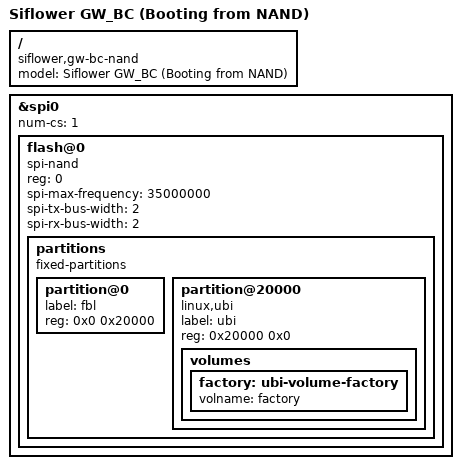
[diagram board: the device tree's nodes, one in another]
/dts-v1/;
#include "sf21h8898-gw-bc.dtsi"


/ {
	model = "Siflower GW_BC (Booting from NAND)";
	compatible = "siflower,gw-bc-nand", "siflower,sf21h8898";
};

&spi0 {
	status = "okay";
	num-cs = <1>;

	flash@0 {
		compatible = "spi-nand";
		reg = <0>;
		spi-max-frequency = <35000000>;
		spi-tx-bus-width = <2>;
		spi-rx-bus-width = <2>;
		#address-cells = <1>;
		#size-cells = <1>;

	        partitions {
			compatible = "fixed-partitions";
			#address-cells = <1>;
			#size-cells = <1>;

			partition@0 {
				label = "fbl";
				reg = <0x0 0x20000>;
			};

			partition@20000 {
				label = "ubi";
				reg = <0x20000 0x0>;
				compatible = "linux,ubi";

				volumes {
					factory: ubi-volume-factory {
						volname = "factory";
					};
				};
			};
		};
	};
};

#include "sf21h8898-factory.dtsi"
